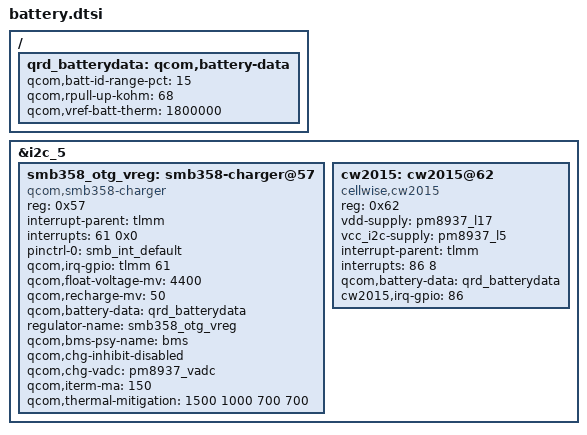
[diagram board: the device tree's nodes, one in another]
/ {
	qrd_batterydata: qcom,battery-data {
		qcom,batt-id-range-pct = <15>;
		qcom,rpull-up-kohm = <68>;
		qcom,vref-batt-therm = <1800000>;

		#include "batterydata/batterydata-wingtech-feimaotui_SONY-4v4-3030mah.dtsi"
		#include "batterydata/batterydata-wingtech-xingwangda_ATL-4v4-3030mah.dtsi"
	};
};

&i2c_5 {
	status = "ok";
	smb358_otg_vreg: smb358-charger@57 {
		compatible = "qcom,smb358-charger";
		reg = <0x57>;
		interrupt-parent = <&tlmm>;
		interrupts = <61 0x0>;
		pinctrl-names = "default";
		pinctrl-0 = <&smb_int_default>;
		qcom,irq-gpio = <&tlmm 61 0x0>;
		qcom,float-voltage-mv = <4400>;
		qcom,recharge-mv = <50>;
		qcom,battery-data = <&qrd_batterydata>;
		regulator-name = "smb358_otg_vreg";
		qcom,bms-psy-name = "bms";
		qcom,chg-inhibit-disabled;	
		qcom,chg-vadc = <&pm8937_vadc>;
		qcom,iterm-ma = <150>;
		/* Optional Properties */
		qcom,thermal-mitigation = <1500 1000 700 700>;
		status = "ok";
	};
	cw2015: cw2015@62 {
		compatible = "cellwise,cw2015";
		reg = <0x62>;
		vdd-supply = <&pm8937_l17>;
		vcc_i2c-supply = <&pm8937_l5>;
		interrupt-parent = <&tlmm>;
		interrupts = <86 8>;
		qcom,battery-data = <&qrd_batterydata>;
		cw2015,irq-gpio=<86>;
	};
};
